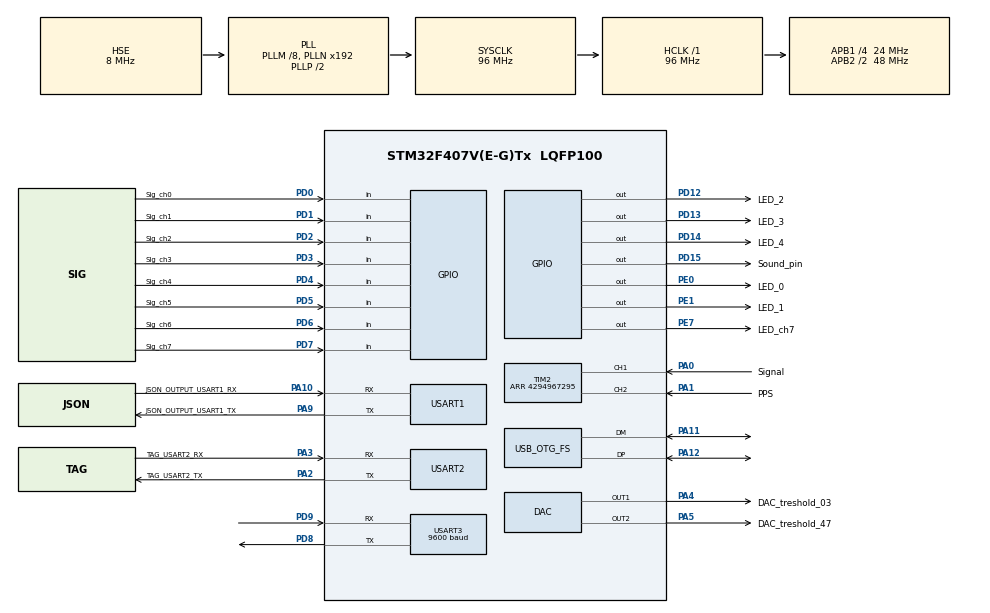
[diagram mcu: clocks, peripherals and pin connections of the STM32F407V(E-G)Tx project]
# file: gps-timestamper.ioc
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FREERTOS.Tasks01=defaultTask,0,1024,StartDefaultTask,Default
Mcu.Family=STM32F4
Mcu.Name=STM32F407V(E-G)Tx
Mcu.Package=LQFP100
NVIC.OTG_FS_IRQn=true\:6\:0\:true\:false\:true\:true\:true
NVIC.PriorityGroup=NVIC_PRIORITYGROUP_4
NVIC.TIM2_IRQn=true\:5\:0\:false\:false\:true\:true\:true
NVIC.TIM6_DAC_IRQn=true\:0\:0\:false\:false\:true\:false\:true
NVIC.TimeBase=TIM6_DAC_IRQn
NVIC.TimeBaseIP=TIM6
NVIC.USART3_IRQn=true\:6\:0\:true\:false\:true\:true\:true
PA0-WKUP.GPIO_Label=Signal
PA0-WKUP.GPIO_ModeDefaultPP=GPIO_MODE_AF_PP
PA0-WKUP.GPIO_PuPd=GPIO_PULLDOWN
PA0-WKUP.Signal=S_TIM2_CH1_ETR
PA1.GPIO_Label=PPS
PA1.GPIO_ModeDefaultPP=GPIO_MODE_AF_PP
PA1.GPIO_PuPd=GPIO_PULLUP
PA1.Signal=S_TIM2_CH2
PA10.GPIO_Label=JSON_OUTPUT_USART1_RX
PA10.Mode=Asynchronous
PA10.Signal=USART1_RX
PA11.Mode=Device_Only
PA11.Signal=USB_OTG_FS_DM
PA12.Mode=Device_Only
PA12.Signal=USB_OTG_FS_DP
PA13.Mode=Serial_Wire
PA13.Signal=SYS_JTMS-SWDIO
PA14.Mode=Serial_Wire
PA14.Signal=SYS_JTCK-SWCLK
PA2.GPIO_Label=TAG_USART2_TX
PA2.Mode=Asynchronous
PA2.Signal=USART2_TX
PA3.GPIO_Label=TAG_USART2_RX
PA3.Mode=Asynchronous
PA3.Signal=USART2_RX
PA4.GPIO_Label=DAC_treshold_03
PA4.Signal=COMP_DAC1_group
PA5.GPIO_Label=DAC_treshold_47
PA5.Signal=COMP_DAC2_group
PA9.GPIO_Label=JSON_OUTPUT_USART1_TX
PA9.Mode=Asynchronous
PA9.Signal=USART1_TX
PD0.GPIO_Label=Sig_ch0
PD0.Signal=GPIO_Input
PD1.GPIO_Label=Sig_ch1
PD1.Signal=GPIO_Input
PD12.GPIO_Label=LED_2
PD12.Signal=GPIO_Output
PD13.GPIO_Label=LED_3
PD13.Signal=GPIO_Output
PD14.GPIO_Label=LED_4
PD14.Signal=GPIO_Output
PD15.GPIO_Label=Sound_pin
PD15.Signal=GPIO_Output
PD2.GPIO_Label=Sig_ch2
PD2.Signal=GPIO_Input
PD3.GPIO_Label=SIg_ch3
PD3.Signal=GPIO_Input
PD4.GPIO_Label=Sig_ch4
PD4.Signal=GPIO_Input
PD5.GPIO_Label=Sig_ch5
PD5.Signal=GPIO_Input
PD6.GPIO_Label=Sig_ch6
PD6.Signal=GPIO_Input
PD7.GPIO_Label=Sig_ch7
PD7.Signal=GPIO_Input
PD8.Mode=Asynchronous
PD8.Signal=USART3_TX
PD9.Mode=Asynchronous
PD9.Signal=USART3_RX
PE0.GPIO_Label=LED_0
PE0.Signal=GPIO_Output
PE1.GPIO_Label=LED_1
PE1.Signal=GPIO_Output
PE7.GPIO_Label=LED_ch7
PE7.Signal=GPIO_Output
PH0-OSC_IN.Mode=HSE-External-Oscillator
PH0-OSC_IN.Signal=RCC_OSC_IN
PH1-OSC_OUT.Mode=HSE-External-Oscillator
PH1-OSC_OUT.Signal=RCC_OSC_OUT
ProjectManager.HeapSize=0x200
ProjectManager.StackSize=0x400
ProjectManager.TargetToolchain=SW4STM32
RCC.48MHZClocksFreq_Value=48000000
RCC.AHBFreq_Value=96000000
RCC.APB1CLKDivider=RCC_HCLK_DIV4
RCC.APB1Freq_Value=24000000
RCC.APB1TimFreq_Value=48000000
RCC.APB2CLKDivider=RCC_HCLK_DIV2
RCC.APB2Freq_Value=48000000
RCC.APB2TimFreq_Value=96000000
RCC.CortexFreq_Value=96000000
RCC.HCLKFreq_Value=96000000
RCC.HSE_VALUE=8000000
RCC.HSI_VALUE=16000000
RCC.LSE_VALUE=32768
RCC.PLLM=8
RCC.SYSCLKFreq_VALUE=96000000
RCC.SYSCLKSource=RCC_SYSCLKSOURCE_PLLCLK
RCC.VCOOutputFreq_Value=192000000
SH.COMP_DAC1_group.0=DAC_OUT1,DAC_OUT1
SH.COMP_DAC2_group.0=DAC_OUT2,DAC_OUT2
SH.S_TIM2_CH1_ETR.0=TIM2_CH1,Input_Capture1_from_TI1
SH.S_TIM2_CH2.0=TIM2_CH2,Input_Capture2_from_TI2
TIM2.Channel-Input_Capture1_from_TI1=TIM_CHANNEL_1
TIM2.Channel-Input_Capture2_from_TI2=TIM_CHANNEL_2
TIM2.ICPolarity_CH1=TIM_INPUTCHANNELPOLARITY_RISING
TIM2.Period=4294967295
USART1.VirtualMode=VM_ASYNC
USART2.VirtualMode=VM_ASYNC
USART3.BaudRate=9600
USART3.VirtualMode=VM_ASYNC
USB_DEVICE.CLASS_NAME-CDC_FS=CDC
USB_DEVICE.CLASS_NAME_FS=CDC
USB_DEVICE.USBD_HandleTypeDef-CDC_FS=hUsbDeviceFS
USB_DEVICE.VirtualMode-CDC_FS=Cdc
USB_DEVICE.VirtualModeFS=Cdc_FS
USB_OTG_FS.VirtualMode=Device_Only
VP_FREERTOS_VS_ENABLE.Mode=Enabled
VP_SYS_VS_tim6.Mode=TIM6
VP_TIM2_VS_ClockSourceINT.Mode=Internal
VP_USB_DEVICE_VS_USB_DEVICE_CDC_FS.Mode=CDC_FS
board=gps-timestamper

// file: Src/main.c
/* USER CODE BEGIN Header */
/**
  ******************************************************************************
  * @file           : main.c
  * @brief          : Main program body
  ******************************************************************************
  * This notice applies to any and all portions of this file
  * that are not between comment pairs USER CODE BEGIN and
  * USER CODE END. Other portions of this file, whether
  * inserted by the user or by software development tools
  * are owned by their respective copyright owners.
  *
  * Copyright (c) 2018 STMicroelectronics International N.V.
  * All rights reserved.
  *
  * Redistribution and use in source and binary forms, with or without
  * modification, are permitted, provided that the following conditions are met:
  *
  * 1. Redistribution of source code must retain the above copyright notice,
  *    this list of conditions and the following disclaimer.
  * 2. Redistributions in binary form must reproduce the above copyright notice,
  *    this list of conditions and the following disclaimer in the documentation
  *    and/or other materials provided with the distribution.
  * 3. Neither the name of STMicroelectronics nor the names of other
  *    contributors to this software may be used to endorse or promote products
  *    derived from this software without specific written permission.
  * 4. This software, including modifications and/or derivative works of this
  *    software, must execute solely and exclusively on microcontroller or
  *    microprocessor devices manufactured by or for STMicroelectronics.
  * 5. Redistribution and use of this software other than as permitted under
  *    this license is void and will automatically terminate your rights under
  *    this license.
  *
  * THIS SOFTWARE IS PROVIDED BY STMICROELECTRONICS AND CONTRIBUTORS "AS IS"
  * AND ANY EXPRESS, IMPLIED OR STATUTORY WARRANTIES, INCLUDING, BUT NOT
  * LIMITED TO, THE IMPLIED WARRANTIES OF MERCHANTABILITY, FITNESS FOR A
  * PARTICULAR PURPOSE AND NON-INFRINGEMENT OF THIRD PARTY INTELLECTUAL PROPERTY
  * RIGHTS ARE DISCLAIMED TO THE FULLEST EXTENT PERMITTED BY LAW. IN NO EVENT
  * SHALL STMICROELECTRONICS OR CONTRIBUTORS BE LIABLE FOR ANY DIRECT, INDIRECT,
  * INCIDENTAL, SPECIAL, EXEMPLARY, OR CONSEQUENTIAL DAMAGES (INCLUDING, BUT NOT
  * LIMITED TO, PROCUREMENT OF SUBSTITUTE GOODS OR SERVICES; LOSS OF USE, DATA,
  * OR PROFITS; OR BUSINESS INTERRUPTION) HOWEVER CAUSED AND ON ANY THEORY OF
  * LIABILITY, WHETHER IN CONTRACT, STRICT LIABILITY, OR TORT (INCLUDING
  * NEGLIGENCE OR OTHERWISE) ARISING IN ANY WAY OUT OF THE USE OF THIS SOFTWARE,
  * EVEN IF ADVISED OF THE POSSIBILITY OF SUCH DAMAGE.
  *
  ******************************************************************************
  */
/* USER CODE END Header */

#include "main.h"
#include "cmsis_os.h"
#include "dac.h"
#include "tim.h"
#include "usart.h"
#include "usb_device.h"
#include "gpio.h"

/* USER CODE BEGIN PV */
/* Private variables ---------------------------------------------------------*/

/* USER CODE END PV */

void SystemClock_Config(void);
void MX_FREERTOS_Init(void);
/* USER CODE BEGIN PFP */
/* Private function prototypes -----------------------------------------------*/

/* USER CODE END PFP */

int main(void)
{

  /* MCU Configuration--------------------------------------------------------*/

  /* Reset of all peripherals, Initializes the Flash interface and the Systick. */
  HAL_Init();

  /* Configure the system clock */
  SystemClock_Config();

  /* Initialize all configured peripherals */
  MX_GPIO_Init();
  MX_USART3_UART_Init();
  MX_TIM2_Init();
  MX_DAC_Init();
  MX_USART1_UART_Init();
  MX_USART2_UART_Init();

  /* Call init function for freertos objects (in freertos.c) */
  MX_FREERTOS_Init();

  /* Start scheduler */
  osKernelStart();

  /* We should never get here as control is now taken by the scheduler */

  /* Infinite loop */
  while (1)
  {

  }
}

void SystemClock_Config(void)
{
  RCC_OscInitTypeDef RCC_OscInitStruct = {0};
  RCC_ClkInitTypeDef RCC_ClkInitStruct = {0};

  /**Configure the main internal regulator output voltage
  */
  __HAL_RCC_PWR_CLK_ENABLE();
  __HAL_PWR_VOLTAGESCALING_CONFIG(PWR_REGULATOR_VOLTAGE_SCALE1);
  /**Initializes the CPU, AHB and APB busses clocks
  */
  RCC_OscInitStruct.OscillatorType = RCC_OSCILLATORTYPE_HSE;
  RCC_OscInitStruct.HSEState = RCC_HSE_ON;
  RCC_OscInitStruct.PLL.PLLState = RCC_PLL_ON;
  RCC_OscInitStruct.PLL.PLLSource = RCC_PLLSOURCE_HSE;
  RCC_OscInitStruct.PLL.PLLM = 8;
  RCC_OscInitStruct.PLL.PLLN = 192;
  RCC_OscInitStruct.PLL.PLLP = RCC_PLLP_DIV2;
  RCC_OscInitStruct.PLL.PLLQ = 4;
  if (HAL_RCC_OscConfig(&RCC_OscInitStruct) != HAL_OK)
  {
    Error_Handler();
  }
  /**Initializes the CPU, AHB and APB busses clocks
  */
  RCC_ClkInitStruct.ClockType = RCC_CLOCKTYPE_HCLK|RCC_CLOCKTYPE_SYSCLK
                              |RCC_CLOCKTYPE_PCLK1|RCC_CLOCKTYPE_PCLK2;
  RCC_ClkInitStruct.SYSCLKSource = RCC_SYSCLKSOURCE_PLLCLK;
  RCC_ClkInitStruct.AHBCLKDivider = RCC_SYSCLK_DIV1;
  RCC_ClkInitStruct.APB1CLKDivider = RCC_HCLK_DIV4;
  RCC_ClkInitStruct.APB2CLKDivider = RCC_HCLK_DIV2;

  if (HAL_RCC_ClockConfig(&RCC_ClkInitStruct, FLASH_LATENCY_3) != HAL_OK)
  {
    Error_Handler();
  }
}

void HAL_TIM_PeriodElapsedCallback(TIM_HandleTypeDef *htim)
{
  if (htim->Instance == TIM6) {
    HAL_IncTick();
  }
}

void Error_Handler(void)
{
}

#ifdef  USE_FULL_ASSERT
/**
  * @brief  Reports the name of the source file and the source line number
  *         where the assert_param error has occurred.
  * @param  file: pointer to the source file name
  * @param  line: assert_param error line source number
  * @retval None
  */
void assert_failed(uint8_t *file, uint32_t line)
{
  /* USER CODE BEGIN 6 */
  printf("Wrong parameters value: file %s on line %d\r\n", file, (int) line);
  /* User can add his own implementation to report the file name and line number,
    ex: printf("Wrong parameters value: file %s on line %d\r\n", file, line) */
  /* USER CODE END 6 */
}
#endif /* USE_FULL_ASSERT */

/************************ (C) COPYRIGHT STMicroelectronics *****END OF FILE****/

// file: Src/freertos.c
/* USER CODE BEGIN Header */
/**
  ******************************************************************************
  * File Name          : freertos.c
  * Description        : Code for freertos applications
  ******************************************************************************
  * This notice applies to any and all portions of this file
  * that are not between comment pairs USER CODE BEGIN and
  * USER CODE END. Other portions of this file, whether
  * inserted by the user or by software development tools
  * are owned by their respective copyright owners.
  *
  * Copyright (c) 2018 STMicroelectronics International N.V.
  * All rights reserved.
  *
  * Redistribution and use in source and binary forms, with or without
  * modification, are permitted, provided that the following conditions are met:
  *
  * 1. Redistribution of source code must retain the above copyright notice,
  *    this list of conditions and the following disclaimer.
  * 2. Redistributions in binary form must reproduce the above copyright notice,
  *    this list of conditions and the following disclaimer in the documentation
  *    and/or other materials provided with the distribution.
  * 3. Neither the name of STMicroelectronics nor the names of other
  *    contributors to this software may be used to endorse or promote products
  *    derived from this software without specific written permission.
  * 4. This software, including modifications and/or derivative works of this
  *    software, must execute solely and exclusively on microcontroller or
  *    microprocessor devices manufactured by or for STMicroelectronics.
  * 5. Redistribution and use of this software other than as permitted under
  *    this license is void and will automatically terminate your rights under
  *    this license.
  *
  * THIS SOFTWARE IS PROVIDED BY STMICROELECTRONICS AND CONTRIBUTORS "AS IS"
  * AND ANY EXPRESS, IMPLIED OR STATUTORY WARRANTIES, INCLUDING, BUT NOT
  * LIMITED TO, THE IMPLIED WARRANTIES OF MERCHANTABILITY, FITNESS FOR A
  * PARTICULAR PURPOSE AND NON-INFRINGEMENT OF THIRD PARTY INTELLECTUAL PROPERTY
  * RIGHTS ARE DISCLAIMED TO THE FULLEST EXTENT PERMITTED BY LAW. IN NO EVENT
  * SHALL STMICROELECTRONICS OR CONTRIBUTORS BE LIABLE FOR ANY DIRECT, INDIRECT,
  * INCIDENTAL, SPECIAL, EXEMPLARY, OR CONSEQUENTIAL DAMAGES (INCLUDING, BUT NOT
  * LIMITED TO, PROCUREMENT OF SUBSTITUTE GOODS OR SERVICES; LOSS OF USE, DATA,
  * OR PROFITS; OR BUSINESS INTERRUPTION) HOWEVER CAUSED AND ON ANY THEORY OF
  * LIABILITY, WHETHER IN CONTRACT, STRICT LIABILITY, OR TORT (INCLUDING
  * NEGLIGENCE OR OTHERWISE) ARISING IN ANY WAY OUT OF THE USE OF THIS SOFTWARE,
  * EVEN IF ADVISED OF THE POSSIBILITY OF SUCH DAMAGE.
  *
  ******************************************************************************
  */
/* USER CODE END Header */

#include "FreeRTOS.h"
#include "task.h"
#include "main.h"
#include "cmsis_os.h"

/* USER CODE BEGIN Includes */
#include "gpio.h"
#include "gps-timestamper-entry-point.h"
/* USER CODE END Includes */

osThreadId defaultTaskHandle;

void StartDefaultTask(void const * argument);

extern void MX_USB_DEVICE_Init(void);
void MX_FREERTOS_Init(void); /* (MISRA C 2004 rule 8.1) */

void MX_FREERTOS_Init(void) {

  /* Create the thread(s) */
  /* definition and creation of defaultTask */
  osThreadDef(defaultTask, StartDefaultTask, osPriorityNormal, 0, 1024);
  defaultTaskHandle = osThreadCreate(osThread(defaultTask), NULL);

}

void StartDefaultTask(void const * argument)
{
  /* init code for USB_DEVICE */
  MX_USB_DEVICE_Init();

  /* USER CODE BEGIN StartDefaultTask */
  UNUSED(argument);
  osDelay(2000);
  printf("{event: \"debug\", msg: \"FreeRTOS started successfuly\"}\n");
  entryPoint();

  /* USER CODE END StartDefaultTask */
}

/************************ (C) COPYRIGHT STMicroelectronics *****END OF FILE****/
